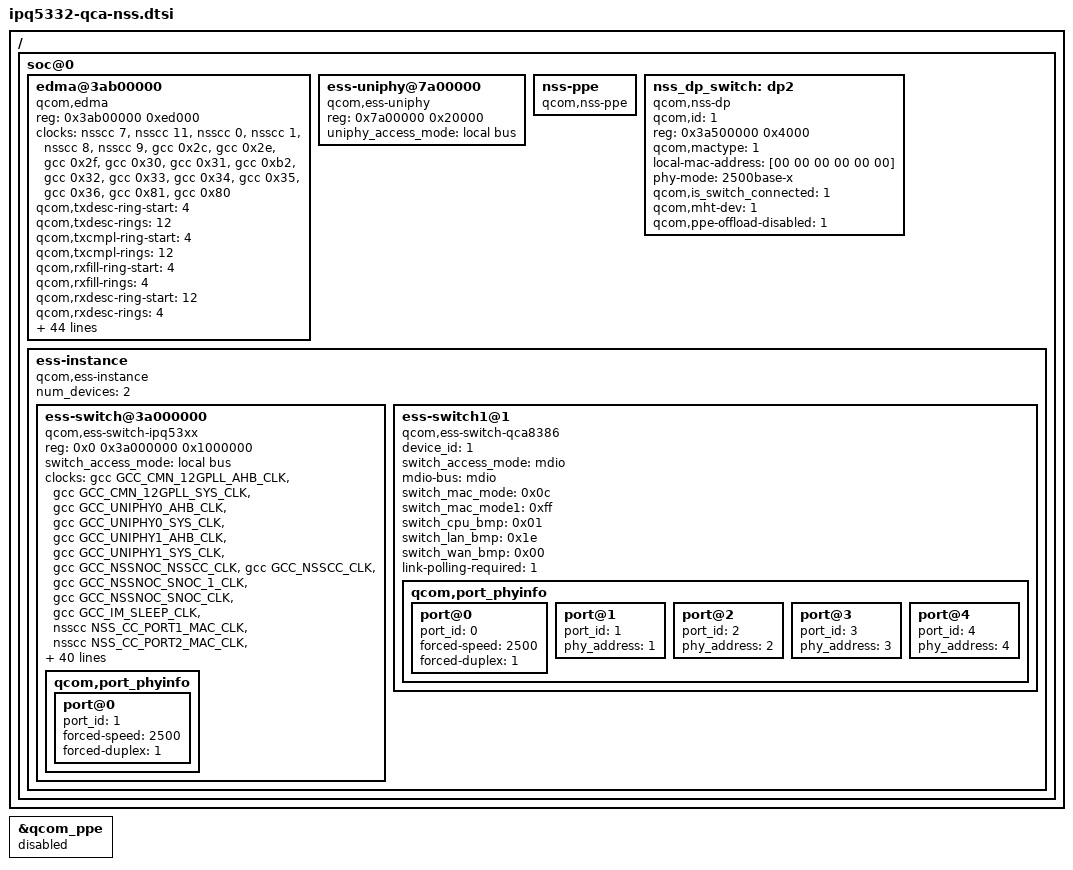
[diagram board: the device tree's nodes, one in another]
// SPDX-License-Identifier: GPL-2.0-only
/*
 * QSDK NSS/PPE ethernet stack (nss-dp + nss-ppe + qca-ssdk).
 *
 * Replaces the mainline "qcom,ipq5332-ppe" driver so that the PPE Direct
 * Switch nodes described by the boot firmware can be used by ath12k.
 * Properties follow the vendor DTB (edma@3ab00000) and the QSDK bindings.
 */
#include <dt-bindings/interrupt-controller/arm-gic.h>
#include <dt-bindings/gpio/gpio.h>

/* the mainline PPE driver cannot share the hardware with nss-dp */
&qcom_ppe {
	status = "disabled";
};

/ {
	soc@0 {
		edma@3ab00000 {
			compatible = "qcom,edma";
			reg = <0x3ab00000 0xed000>;
			reg-names = "edma-reg-base";
			reset-names = "edma_rst";
			clocks = <&nsscc 7>, <&nsscc 11>, <&nsscc 0>, <&nsscc 1>,
				 <&nsscc 8>, <&nsscc 9>, <&gcc 0x2c>, <&gcc 0x2e>,
				 <&gcc 0x2f>, <&gcc 0x30>, <&gcc 0x31>, <&gcc 0xb2>,
				 <&gcc 0x32>, <&gcc 0x33>, <&gcc 0x34>, <&gcc 0x35>,
				 <&gcc 0x36>, <&gcc 0x81>, <&gcc 0x80>;
			clock-names = "nss-csr-clk", "nss-nssnoc-csr-clk",
				      "nss-ce-ahb-clk", "nss-ce-axi-clk",
				      "nss-nssnoc-ce-ahb-clk", "nss-nssnoc-ce-axi-clk",
				      "nss-ts-clk", "nss-nsscc-clk", "nss-nsscfg-clk",
				      "nss-nssnoc-atb-clk", "nss-nssnoc-nsscc-clk",
				      "nss-nssnoc-pcnoc-1-clk", "nss-nssnoc-qosgen-ref-clk",
				      "nss-nssnoc-snoc-1-clk", "nss-nssnoc-snoc-clk",
				      "nss-nssnoc-timeout-ref-clk", "nss-nssnoc-xo-dcd-clk",
				      "nss-snoc-nssnoc-clk", "nss-snoc-nssnoc-1-clk";

			qcom,txdesc-ring-start = <4>;
			qcom,txdesc-rings = <12>;
			qcom,txcmpl-ring-start = <4>;
			qcom,txcmpl-rings = <12>;
			qcom,rxfill-ring-start = <4>;
			qcom,rxfill-rings = <4>;
			qcom,rxdesc-ring-start = <12>;
			qcom,rxdesc-rings = <4>;
			qcom,rx-page-mode = <0>;
			qcom,tx-map-priority-level = <1>;
			qcom,rx-map-priority-level = <1>;

			/* two Direct Switch nodes: one per WLAN radio */
			qcom,ppeds-num = <2>;
			qcom,ppeds-map = <1 1 1 1 0x20 0x08
					  2 2 2 2 0x28 0x08>;

			qcom,txdesc-map = <8 9 10 11 12 13 14 15
					   4 5 6 7>;
			qcom,txdesc-fc-grp-map = <1 2>;
			qcom,rxfill-map = <4 5 6 7>;
			qcom,rxdesc-map = <12 13 14 15>;
			qcom,rx-queue-start = <0>;
			qcom,rx-ring-queue-map = <0 8 0x10 0x18  1 9 0x11 0x19
						  2 10 0x12 0x1a  3 11 0x13 0x1b
						  4 12 0x14 0x1c  5 13 0x15 0x1d
						  6 14 0x16 0x1e  7 15 0x17 0x1f>;

			interrupts = <GIC_SPI 0xa3 IRQ_TYPE_LEVEL_HIGH>,
				     <GIC_SPI 0xa4 IRQ_TYPE_LEVEL_HIGH>,
				     <GIC_SPI 0xa5 IRQ_TYPE_LEVEL_HIGH>,
				     <GIC_SPI 0xa6 IRQ_TYPE_LEVEL_HIGH>,
				     <GIC_SPI 0xa7 IRQ_TYPE_LEVEL_HIGH>,
				     <GIC_SPI 0xa8 IRQ_TYPE_LEVEL_HIGH>,
				     <GIC_SPI 0xa9 IRQ_TYPE_LEVEL_HIGH>,
				     <GIC_SPI 0xaa IRQ_TYPE_LEVEL_HIGH>,
				     <GIC_SPI 0xab IRQ_TYPE_LEVEL_HIGH>,
				     <GIC_SPI 0xac IRQ_TYPE_LEVEL_HIGH>,
				     <GIC_SPI 0xad IRQ_TYPE_LEVEL_HIGH>,
				     <GIC_SPI 0xae IRQ_TYPE_LEVEL_HIGH>,
				     <GIC_SPI 0x8b IRQ_TYPE_LEVEL_HIGH>,
				     <GIC_SPI 0x8c IRQ_TYPE_LEVEL_HIGH>,
				     <GIC_SPI 0x8d IRQ_TYPE_LEVEL_HIGH>,
				     <GIC_SPI 0x8e IRQ_TYPE_LEVEL_HIGH>,
				     <GIC_SPI 0xbf IRQ_TYPE_LEVEL_HIGH>,
				     <GIC_SPI 0xa0 IRQ_TYPE_LEVEL_HIGH>,
				     <GIC_SPI 0x80 IRQ_TYPE_LEVEL_HIGH>,
				     <GIC_SPI 0x98 IRQ_TYPE_LEVEL_HIGH>,
				     <GIC_SPI 0xa1 IRQ_TYPE_LEVEL_HIGH>,
				     <GIC_SPI 0x81 IRQ_TYPE_LEVEL_HIGH>,
				     <GIC_SPI 0x99 IRQ_TYPE_LEVEL_HIGH>,
				     <GIC_SPI 0xaf IRQ_TYPE_LEVEL_HIGH>,
				     <GIC_SPI 0xb0 IRQ_TYPE_LEVEL_HIGH>,
				     <GIC_SPI 0xb1 IRQ_TYPE_LEVEL_HIGH>,
				     <GIC_SPI 0xb2 IRQ_TYPE_LEVEL_HIGH>,
				     <GIC_SPI 0xb3 IRQ_TYPE_LEVEL_HIGH>,
				     <GIC_SPI 0xb4 IRQ_TYPE_LEVEL_HIGH>,
				     <GIC_SPI 0xb5 IRQ_TYPE_LEVEL_HIGH>,
				     <GIC_SPI 0xb6 IRQ_TYPE_LEVEL_HIGH>;
		};

		ess-uniphy@7a00000 {
			compatible = "qcom,ess-uniphy";
			reg = <0x7a00000 0x20000>;
			uniphy_access_mode = "local bus";
		};

		nss-ppe {
			compatible = "qcom,nss-ppe";
		};

		/* CPU port towards the QCA8386 switch.  The switch is driven by
		 * the mainline DSA qca8k driver; its CPU port is this netdev, so
		 * the link is 2500base-X on PCS0 exactly like the mainline PPE
		 * port it replaces.  ppe-offload-disabled keeps the PPE from
		 * claiming the CPU port and stripping the DSA tag.
		 */
		nss_dp_switch: dp2 {
			device_type = "network";
			compatible = "qcom,nss-dp";
			qcom,id = <1>;
			reg = <0x3a500000 0x4000>;
			qcom,mactype = <1>;
			local-mac-address = [00 00 00 00 00 00];
			phy-mode = "2500base-x";
			qcom,is_switch_connected = <1>;
			qcom,mht-dev = <1>;
			qcom,ppe-offload-disabled = <1>;
			status = "okay";
		};

		/* qca-ssdk needs this to bring up the port MACs, the UNIPHY/PCS
		 * instances and the PHY firmware of the QCA8386.  nss-dp itself
		 * only provides the netdevices.
		 */
		ess-instance {
			compatible = "qcom,ess-instance";
			num_devices = <2>;

			ess-switch@3a000000 {
				compatible = "qcom,ess-switch-ipq53xx";
				reg = <0x0 0x3a000000 0x1000000>;
				switch_access_mode = "local bus";
				/* Clock order/names follow the QSDK binding: qca-ssdk
				 * fetches them by name, so the order must not change.
				 * nsscc ids 14/21/33/32/13/12/30/29/34/31/15/18/22/25/
				 * 35/36/37/38 and the gcc ids below are identical to the
				 * vendor DTB numbering.
				 */
				clocks = <&gcc GCC_CMN_12GPLL_AHB_CLK>,
					 <&gcc GCC_CMN_12GPLL_SYS_CLK>,
					 <&gcc GCC_UNIPHY0_AHB_CLK>,
					 <&gcc GCC_UNIPHY0_SYS_CLK>,
					 <&gcc GCC_UNIPHY1_AHB_CLK>,
					 <&gcc GCC_UNIPHY1_SYS_CLK>,
					 <&gcc GCC_NSSNOC_NSSCC_CLK>,
					 <&gcc GCC_NSSCC_CLK>,
					 <&gcc GCC_NSSNOC_SNOC_1_CLK>,
					 <&gcc GCC_NSSNOC_SNOC_CLK>,
					 <&gcc GCC_IM_SLEEP_CLK>,
					 <&nsscc NSS_CC_PORT1_MAC_CLK>,
					 <&nsscc NSS_CC_PORT2_MAC_CLK>,
					 <&nsscc NSS_CC_PPE_SWITCH_CLK>,
					 <&nsscc NSS_CC_PPE_SWITCH_CFG_CLK>,
					 <&nsscc NSS_CC_NSSNOC_PPE_CLK>,
					 <&nsscc NSS_CC_NSSNOC_PPE_CFG_CLK>,
					 <&nsscc NSS_CC_PPE_EDMA_CLK>,
					 <&nsscc NSS_CC_PPE_EDMA_CFG_CLK>,
					 <&nsscc NSS_CC_PPE_SWITCH_IPE_CLK>,
					 <&nsscc NSS_CC_PPE_SWITCH_BTQ_CLK>,
					 <&nsscc NSS_CC_PORT1_RX_CLK>,
					 <&nsscc NSS_CC_PORT1_TX_CLK>,
					 <&nsscc NSS_CC_PORT2_RX_CLK>,
					 <&nsscc NSS_CC_PORT2_TX_CLK>,
					 <&nsscc NSS_CC_UNIPHY_PORT1_RX_CLK>,
					 <&nsscc NSS_CC_UNIPHY_PORT1_TX_CLK>,
					 <&nsscc NSS_CC_UNIPHY_PORT2_RX_CLK>,
					 <&nsscc NSS_CC_UNIPHY_PORT2_TX_CLK>;
				clock-names = "cmn_ahb_clk", "cmn_sys_clk",
					      "uniphy0_ahb_clk", "uniphy0_sys_clk",
					      "uniphy1_ahb_clk", "uniphy1_sys_clk",
					      "gcc_nssnoc_nsscc_clk", "gcc_nsscc_clk",
					      "gcc_nssnoc_snoc_1_clk", "gcc_nssnoc_snoc_clk",
					      "gcc_im_sleep_clk",
					      "port1_mac_clk", "port2_mac_clk",
					      "nss_ppe_clk", "nss_ppe_cfg_clk",
					      "nssnoc_ppe_clk", "nssnoc_ppe_cfg_clk",
					      "nss_edma_clk", "nss_edma_cfg_clk",
					      "nss_ppe_ipe_clk", "nss_ppe_btq_clk",
					      "nss_port1_rx_clk", "nss_port1_tx_clk",
					      "nss_port2_rx_clk", "nss_port2_tx_clk",
					      "uniphy0_port1_rx_clk", "uniphy0_port1_tx_clk",
					      "uniphy1_port5_rx_clk", "uniphy1_port5_tx_clk";
				/* ppe_rst is nsscc id 17 (NSS_CC_PPE_BCR); the uniphy
				 * soft resets are the gcc BCRs (121/124).
				 */
				resets = <&nsscc NSS_CC_PPE_BCR>,
					 <&gcc GCC_UNIPHY0_BCR>,
					 <&gcc GCC_UNIPHY1_BCR>,
					 <&gcc GCC_UNIPHY0_AHB_CLK_ARES>,
					 <&gcc GCC_UNIPHY1_AHB_CLK_ARES>,
					 <&gcc GCC_UNIPHY0_SYS_CLK_ARES>,
					 <&gcc GCC_UNIPHY1_SYS_CLK_ARES>,
					 <&gcc GCC_UNIPHY0_XPCS_ARES>,
					 <&gcc GCC_UNIPHY1_XPCS_ARES>,
					 <&nsscc NSS_CC_UNIPHY_PORT1_RX_CLK_ARES>,
					 <&nsscc NSS_CC_UNIPHY_PORT1_TX_CLK_ARES>,
					 <&nsscc NSS_CC_UNIPHY_PORT2_RX_CLK_ARES>,
					 <&nsscc NSS_CC_UNIPHY_PORT2_TX_CLK_ARES>,
					 <&nsscc NSS_CC_PORT1_RX_CLK_ARES>,
					 <&nsscc NSS_CC_PORT1_TX_CLK_ARES>,
					 <&nsscc NSS_CC_PORT2_RX_CLK_ARES>,
					 <&nsscc NSS_CC_PORT2_TX_CLK_ARES>,
					 <&nsscc NSS_CC_PORT1_MAC_CLK_ARES>,
					 <&nsscc NSS_CC_PORT2_MAC_CLK_ARES>;
				reset-names = "ppe_rst",
					      "uniphy0_soft_rst", "uniphy1_soft_rst",
					      "uniphy0_ahb_rst", "uniphy1_ahb_rst",
					      "uniphy0_sys_rst", "uniphy1_sys_rst",
					      "uniphy0_xpcs_rst", "uniphy1_xpcs_rst",
					      "uniphy_port1_rx_rst", "uniphy_port1_tx_rst",
					      "uniphy_port2_rx_rst", "uniphy_port2_tx_rst",
					      "nss_port1_rx_rst", "nss_port1_tx_rst",
					      "nss_port2_rx_rst", "nss_port2_tx_rst",
					      "nss_port1_mac_rst", "nss_port2_mac_rst";
				switch_cpu_bmp = <0x01>;
				switch_lan_bmp = <0x02>;
				switch_wan_bmp = <0x04>;
				/* 0xc = 2500base-X on the CPU port (as the mainline
				 * PPE port did), the other two MACs are unused.
				 */
				switch_mac_mode = <0x0c>;
				switch_mac_mode1 = <0xff>;
				switch_mac_mode2 = <0xff>;

				qcom,port_phyinfo {
					port@0 {
						port_id = <1>;
						forced-speed = <2500>;
						forced-duplex = <1>;
					};
				};
			};

			ess-switch1@1 {
				compatible = "qcom,ess-switch-qca8386";
				device_id = <1>;
				switch_access_mode = "mdio";
				mdio-bus = <&mdio>;
				switch_mac_mode = <0x0c>;
				switch_mac_mode1 = <0xff>;
				switch_cpu_bmp = <0x01>;
				/* four copper ports live on this switch: lan1..lan3 + wan */
				switch_lan_bmp = <0x1e>;
				switch_wan_bmp = <0x00>;
				/* No link interrupt is defined for this board, so let
				 * qca-ssdk poll the PHYs. Do not guess a GPIO here.
				 */
				link-polling-required = <1>;

				qcom,port_phyinfo {
					port@0 {
						port_id = <0>;
						forced-speed = <2500>;
						forced-duplex = <1>;
					};

					port@1 {
						port_id = <1>;
						phy_address = <1>;
					};

					port@2 {
						port_id = <2>;
						phy_address = <2>;
					};

					port@3 {
						port_id = <3>;
						phy_address = <3>;
					};

					port@4 {
						port_id = <4>;
						phy_address = <4>;
					};
				};
			};
		};
	};
};
